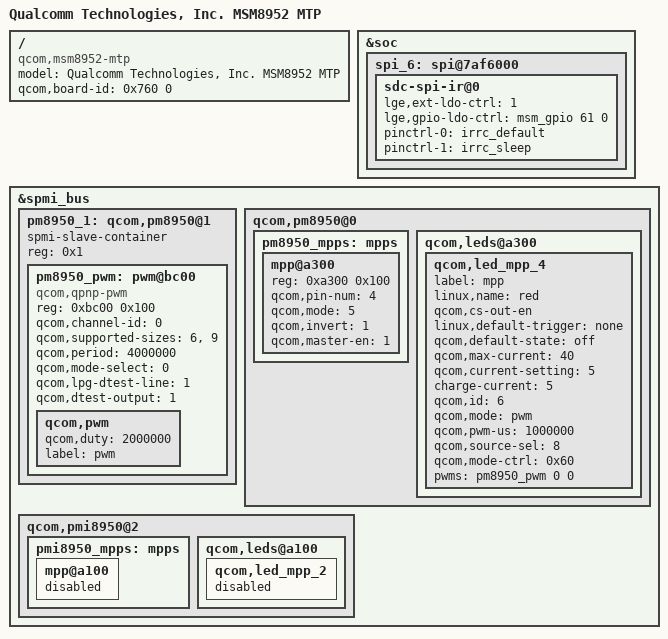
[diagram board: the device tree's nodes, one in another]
/*
 * Copyright (c) 2015, The Linux Foundation. All rights reserved.
 *
 * This program is free software; you can redistribute it and/or modify
 * it under the terms of the GNU General Public License version 2 and
 * only version 2 as published by the Free Software Foundation.
 *
 * This program is distributed in the hope that it will be useful,
 * but WITHOUT ANY WARRANTY; without even the implied warranty of
 * MERCHANTABILITY or FITNESS FOR A PARTICULAR PURPOSE.  See the
 * GNU General Public License for more details.
 */

/dts-v1/;

#include "msm8952-p1v_att_us.dtsi"

/ {
	model = "Qualcomm Technologies, Inc. MSM8952 MTP";
	compatible = "qcom,msm8952-mtp", "qcom,msm8952", "qcom,mtp", "lge,msm8952-p1v_att_us";
	qcom,board-id= <0x760 0>; /* rev_1.1 */
};

&soc {
	spi_6: spi@7af6000 {
		sdc-spi-ir@0 {
			lge,ext-ldo-ctrl = <1>;
			lge,gpio-ldo-ctrl = <&msm_gpio 61 0>;
			pinctrl-names = "irrc_default", "irrc_sleep";
			pinctrl-0 = <&irrc_default>;
			pinctrl-1 = <&irrc_sleep>;
		};
	};
};

&spmi_bus {

	pm8950_1: qcom,pm8950@1 {
		spmi-slave-container;
		reg = <0x1>;
		#address-cells = <1>;
		#size-cells = <1>;
		pm8950_pwm: pwm@bc00 {
			compatible = "qcom,qpnp-pwm";
			reg = <0xbc00 0x100>;
			reg-names = "qpnp-lpg-channel-base";
			qcom,channel-id = <0>;
			qcom,supported-sizes = <6>, <9>;
			qcom,period = <4000000>;
			qcom,mode-select = <0>;
			qcom,lpg-dtest-line = <1>;
			qcom,dtest-output = <1>;
			#pwm-cells = <2>;
			// Adds this line.
			qcom,pwm {
				qcom,duty = <2000000>; //PWM duty time in microseconds
				label = "pwm";
			};
		};

	};

	qcom,pm8950@0 {
		pm8950_mpps: mpps {
			mpp@a300 {
				/* MPP4  LED */
				reg = <0xa300 0x100>;
				qcom,pin-num = <4>;
				qcom,mode = <5>;
				qcom,invert = <1>;
				qcom,master-en = <1>;
			};
		};

		qcom,leds@a300 {
			status = "okay";
			qcom,led_mpp_4 {
				label = "mpp";
				linux,name = "red";
				qcom,cs-out-en;
				linux,default-trigger = "none";
				qcom,default-state = "off";
				qcom,max-current = <40>;
				qcom,current-setting = <5>;
				charge-current = <5>;
				qcom,id = <6>;
				qcom,mode = "pwm";
				qcom,pwm-us = <1000000>;
				qcom,source-sel = <8>;
				qcom,mode-ctrl = <0x60>;
				pwms = <&pm8950_pwm 0 0>;
			};
		};
	};

	qcom,pmi8950@2 {
		pmi8950_mpps: mpps {
			mpp@a100 {
				status = "disabled";
			};
		};
		qcom,leds@a100 {
			status = "okay";
			qcom,led_mpp_2 {
				status = "disabled";
			};
		};
	};

};
